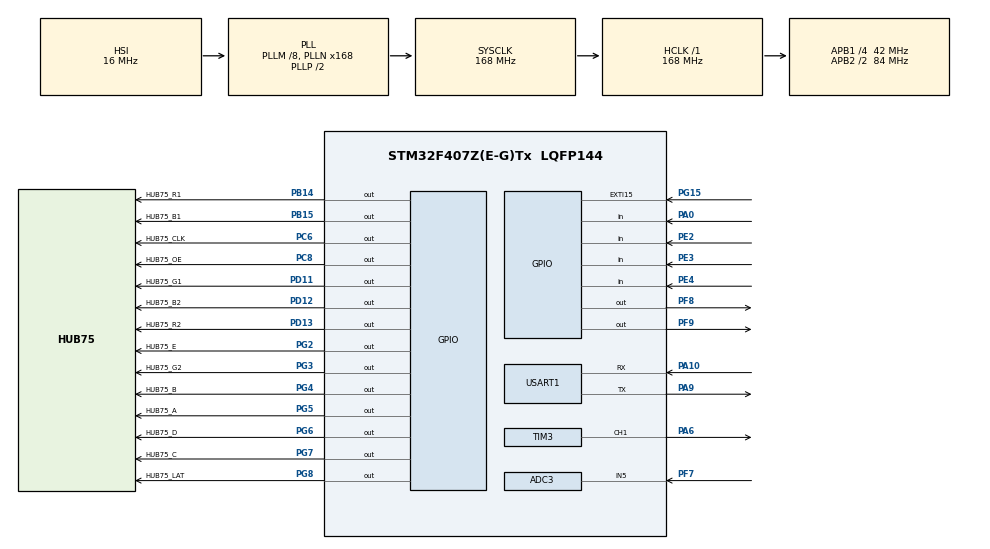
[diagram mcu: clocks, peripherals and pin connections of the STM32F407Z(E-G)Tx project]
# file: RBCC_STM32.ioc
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ADC1.Channel-0\#ChannelRegularConversion=ADC_CHANNEL_TEMPSENSOR
ADC1.NbrOfConversionFlag=1
ADC1.Rank-0\#ChannelRegularConversion=1
ADC1.SamplingTime-0\#ChannelRegularConversion=ADC_SAMPLETIME_480CYCLES
ADC1.master=1
ADC3.Channel-0\#ChannelRegularConversion=ADC_CHANNEL_5
ADC3.NbrOfConversionFlag=1
ADC3.Rank-0\#ChannelRegularConversion=1
ADC3.SamplingTime-0\#ChannelRegularConversion=ADC_SAMPLETIME_480CYCLES
Mcu.Family=STM32F4
Mcu.Name=STM32F407Z(E-G)Tx
Mcu.Package=LQFP144
NVIC.EXTI15_10_IRQn=true\:1\:0\:true\:false\:true\:true\:true\:true
NVIC.PriorityGroup=NVIC_PRIORITYGROUP_4
NVIC.TIM2_IRQn=true\:0\:0\:false\:false\:true\:true\:true\:true
NVIC.USART1_IRQn=true\:0\:0\:false\:false\:true\:true\:true\:true
PA0-WKUP.GPIO_PuPd=GPIO_PULLDOWN
PA0-WKUP.Signal=GPIO_Input
PA10.Mode=Asynchronous
PA10.Signal=USART1_RX
PA13.Mode=Serial_Wire
PA13.Signal=SYS_JTMS-SWDIO
PA14.Mode=Serial_Wire
PA14.Signal=SYS_JTCK-SWCLK
PA6.Signal=S_TIM3_CH1
PA9.Mode=Asynchronous
PA9.Signal=USART1_TX
PB14.GPIO_Label=HUB75_R1
PB14.GPIO_Speed=GPIO_SPEED_FREQ_VERY_HIGH
PB14.PinState=GPIO_PIN_SET
PB14.Signal=GPIO_Output
PB15.GPIO_Label=HUB75_B1
PB15.GPIO_Speed=GPIO_SPEED_FREQ_HIGH
PB15.Signal=GPIO_Output
PC6.GPIO_Label=HUB75_CLK
PC6.GPIO_Speed=GPIO_SPEED_FREQ_VERY_HIGH
PC6.Signal=GPIO_Output
PC8.GPIO_Label=HUB75_OE
PC8.GPIO_Speed=GPIO_SPEED_FREQ_VERY_HIGH
PC8.PinState=GPIO_PIN_SET
PC8.Signal=GPIO_Output
PD11.GPIO_Label=HUB75_G1
PD11.GPIO_Speed=GPIO_SPEED_FREQ_HIGH
PD11.Signal=GPIO_Output
PD12.GPIO_Label=HUB75_B2
PD12.GPIO_Speed=GPIO_SPEED_FREQ_HIGH
PD12.Signal=GPIO_Output
PD13.GPIO_Label=HUB75_R2
PD13.GPIO_Speed=GPIO_SPEED_FREQ_HIGH
PD13.Signal=GPIO_Output
PE2.GPIO_PuPd=GPIO_PULLUP
PE2.Signal=GPIO_Input
PE3.GPIO_PuPd=GPIO_PULLUP
PE3.Signal=GPIO_Input
PE4.GPIO_PuPd=GPIO_PULLUP
PE4.Signal=GPIO_Input
PF7.Mode=IN5
PF7.Signal=ADC3_IN5
PF8.GPIO_PuPd=GPIO_PULLUP
PF8.GPIO_Speed=GPIO_SPEED_FREQ_HIGH
PF8.Signal=GPIO_Output
PF9.GPIO_PuPd=GPIO_PULLUP
PF9.GPIO_Speed=GPIO_SPEED_FREQ_HIGH
PF9.PinState=GPIO_PIN_SET
PF9.Signal=GPIO_Output
PG15.GPIO_ModeDefaultEXTI=GPIO_MODE_IT_RISING_FALLING
PG15.Signal=GPXTI15
PG2.GPIO_Label=HUB75_E
PG2.GPIO_Speed=GPIO_SPEED_FREQ_HIGH
PG2.Signal=GPIO_Output
PG3.GPIO_Label=HUB75_G2
PG3.GPIO_Speed=GPIO_SPEED_FREQ_HIGH
PG3.Signal=GPIO_Output
PG4.GPIO_Label=HUB75_B
PG4.GPIO_Speed=GPIO_SPEED_FREQ_HIGH
PG4.Signal=GPIO_Output
PG5.GPIO_Label=HUB75_A
PG5.GPIO_Speed=GPIO_SPEED_FREQ_HIGH
PG5.Signal=GPIO_Output
PG6.GPIO_Label=HUB75_D
PG6.GPIO_Speed=GPIO_SPEED_FREQ_HIGH
PG6.Signal=GPIO_Output
PG7.GPIO_Label=HUB75_C
PG7.GPIO_Speed=GPIO_SPEED_FREQ_HIGH
PG7.Signal=GPIO_Output
PG8.GPIO_Label=HUB75_LAT
PG8.GPIO_Speed=GPIO_SPEED_FREQ_VERY_HIGH
PG8.Signal=GPIO_Output
ProjectManager.HeapSize=0x200
ProjectManager.StackSize=0x400
ProjectManager.TargetToolchain=MDK-ARM V5.32
RCC.48MHZClocksFreq_Value=84000000
RCC.AHBFreq_Value=168000000
RCC.APB1CLKDivider=RCC_HCLK_DIV4
RCC.APB1Freq_Value=42000000
RCC.APB1TimFreq_Value=84000000
RCC.APB2CLKDivider=RCC_HCLK_DIV2
RCC.APB2Freq_Value=84000000
RCC.APB2TimFreq_Value=168000000
RCC.CortexFreq_Value=168000000
RCC.HCLKFreq_Value=168000000
RCC.HSE_VALUE=25000000
RCC.HSI_VALUE=16000000
RCC.LSE_VALUE=32768
RCC.PLLM=8
RCC.PLLN=168
RCC.SYSCLKFreq_VALUE=168000000
RCC.SYSCLKSource=RCC_SYSCLKSOURCE_PLLCLK
RCC.VCOOutputFreq_Value=336000000
SH.S_TIM3_CH1.0=TIM3_CH1,PWM Generation1 CH1
TIM2.AutoReloadPreload=TIM_AUTORELOAD_PRELOAD_DISABLE
TIM2.Prescaler=83
TIM3.AutoReloadPreload=TIM_AUTORELOAD_PRELOAD_ENABLE
TIM3.Channel-PWM\ Generation1\ CH1=TIM_CHANNEL_1
TIM3.Period=999
TIM3.Prescaler=27
TIM3.Pulse-PWM\ Generation1\ CH1=500
USART1.VirtualMode=VM_ASYNC
VP_ADC1_TempSens_Input.Mode=IN-TempSens
VP_TIM2_VS_ClockSourceINT.Mode=Internal
board=custom

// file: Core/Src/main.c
/* USER CODE BEGIN Header */
/**
  ******************************************************************************
  * @file           : main.c
  * @brief          : Main program body
  ******************************************************************************
  * @attention
  *
  * Copyright (c) 2026 STMicroelectronics.
  * All rights reserved.
  *
  * This software is licensed under terms that can be found in the LICENSE file
  * in the root directory of this software component.
  * If no LICENSE file comes with this software, it is provided AS-IS.
  *
  ******************************************************************************
  */
/* USER CODE END Header */
#include "main.h"
#include "adc.h"
#include "tim.h"
#include "usart.h"
#include "gpio.h"

/* USER CODE BEGIN Includes */
#include "scheduler.h"

/* USER CODE END Includes */

void SystemClock_Config(void);

int main(void)
{

  /* MCU Configuration--------------------------------------------------------*/

  /* Reset of all peripherals, Initializes the Flash interface and the Systick. */
  HAL_Init();

  /* Configure the system clock */
  SystemClock_Config();

  /* Initialize all configured peripherals */
  MX_GPIO_Init();
  MX_USART1_UART_Init();
  MX_ADC3_Init();
  MX_ADC1_Init();
  MX_TIM3_Init();
  MX_TIM2_Init();
  /* USER CODE BEGIN 2 */
  schedule_init();

  /* USER CODE END 2 */

  /* Infinite loop */
  while (1)
  {

    /* USER CODE BEGIN 3 */
	  schedule_run();

  }
  /* USER CODE END 3 */
}

void SystemClock_Config(void)
{
  RCC_OscInitTypeDef RCC_OscInitStruct = {0};
  RCC_ClkInitTypeDef RCC_ClkInitStruct = {0};

  /** Configure the main internal regulator output voltage
  */
  __HAL_RCC_PWR_CLK_ENABLE();
  __HAL_PWR_VOLTAGESCALING_CONFIG(PWR_REGULATOR_VOLTAGE_SCALE1);

  /** Initializes the RCC Oscillators according to the specified parameters
  * in the RCC_OscInitTypeDef structure.
  */
  RCC_OscInitStruct.OscillatorType = RCC_OSCILLATORTYPE_HSI;
  RCC_OscInitStruct.HSIState = RCC_HSI_ON;
  RCC_OscInitStruct.HSICalibrationValue = RCC_HSICALIBRATION_DEFAULT;
  RCC_OscInitStruct.PLL.PLLState = RCC_PLL_ON;
  RCC_OscInitStruct.PLL.PLLSource = RCC_PLLSOURCE_HSI;
  RCC_OscInitStruct.PLL.PLLM = 8;
  RCC_OscInitStruct.PLL.PLLN = 168;
  RCC_OscInitStruct.PLL.PLLP = RCC_PLLP_DIV2;
  RCC_OscInitStruct.PLL.PLLQ = 4;
  if (HAL_RCC_OscConfig(&RCC_OscInitStruct) != HAL_OK)
  {
    Error_Handler();
  }

  /** Initializes the CPU, AHB and APB buses clocks
  */
  RCC_ClkInitStruct.ClockType = RCC_CLOCKTYPE_HCLK|RCC_CLOCKTYPE_SYSCLK
                              |RCC_CLOCKTYPE_PCLK1|RCC_CLOCKTYPE_PCLK2;
  RCC_ClkInitStruct.SYSCLKSource = RCC_SYSCLKSOURCE_PLLCLK;
  RCC_ClkInitStruct.AHBCLKDivider = RCC_SYSCLK_DIV1;
  RCC_ClkInitStruct.APB1CLKDivider = RCC_HCLK_DIV4;
  RCC_ClkInitStruct.APB2CLKDivider = RCC_HCLK_DIV2;

  if (HAL_RCC_ClockConfig(&RCC_ClkInitStruct, FLASH_LATENCY_5) != HAL_OK)
  {
    Error_Handler();
  }
}

void Error_Handler(void)
{
  __disable_irq();
  while (1)
  {
  }
}
